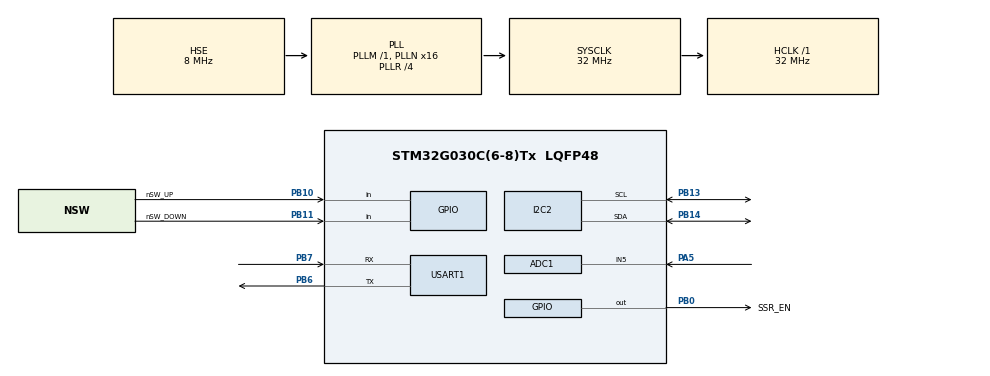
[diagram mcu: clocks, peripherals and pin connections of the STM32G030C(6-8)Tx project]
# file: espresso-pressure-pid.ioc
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ADC1.Channel-1\#ChannelRegularConversion=ADC_CHANNEL_5
ADC1.ContinuousConvMode=ENABLE
ADC1.EnableAnalogWatchDog3=true
ADC1.NbrOfConversion=1
ADC1.NbrOfConversionFlag=1
ADC1.OversamplingMode=ENABLE
ADC1.Rank-1\#ChannelRegularConversion=1
ADC1.Ratio=ADC_OVERSAMPLING_RATIO_16
ADC1.SamplingTime-1\#ChannelRegularConversion=ADC_SAMPLINGTIME_COMMON_1
ADC1.SelectedChannel=ADC_CHANNEL_5
ADC1.master=1
I2C2.Timing=0x00B07CB4
Mcu.Family=STM32G0
Mcu.Name=STM32G030C(6-8)Tx
Mcu.Package=LQFP48
PA13.Mode=Serial_Wire
PA13.Signal=SYS_SWDIO
PA14-BOOT0.Mode=Serial_Wire
PA14-BOOT0.Signal=SYS_SWCLK
PA5.Mode=IN5
PA5.Signal=ADC1_IN5
PB0.GPIO_Label=SSR_EN
PB0.Signal=GPIO_Output
PB10.GPIO_Label=nSW_UP
PB10.Signal=GPIO_Input
PB11.GPIO_Label=nSW_DOWN
PB11.Signal=GPIO_Input
PB13.Mode=I2C
PB13.Signal=I2C2_SCL
PB14.Mode=I2C
PB14.Signal=I2C2_SDA
PB6.GPIO_Speed=GPIO_SPEED_FREQ_VERY_HIGH
PB6.Mode=Asynchronous
PB6.Signal=USART1_TX
PB7.GPIO_Speed=GPIO_SPEED_FREQ_VERY_HIGH
PB7.Mode=Asynchronous
PB7.Signal=USART1_RX
PF0-OSC_IN\ (PF0).Mode=HSE-External-Oscillator
PF0-OSC_IN\ (PF0).Signal=RCC_OSC_IN
PF1-OSC_OUT\ (PF1).Mode=HSE-External-Oscillator
PF1-OSC_OUT\ (PF1).Signal=RCC_OSC_OUT
ProjectManager.HeapSize=0x200
ProjectManager.StackSize=0x400
ProjectManager.TargetToolchain=CMake
RCC.ADCFreq_Value=32000000
RCC.AHBFreq_Value=32000000
RCC.CortexFreq_Value=32000000
RCC.EXTERNAL_CLOCK_VALUE=12288000
RCC.HCLKFreq_Value=32000000
RCC.HSE_VALUE=8000000
RCC.HSI_VALUE=16000000
RCC.LSE_VALUE=32768
RCC.PLLN=16
RCC.PLLR=RCC_PLLR_DIV4
RCC.PLLSourceVirtual=RCC_PLLSOURCE_HSE
RCC.SYSCLKFreq_VALUE=32000000
RCC.SYSCLKSource=RCC_SYSCLKSOURCE_PLLCLK
RCC.USART1CLockSelection=RCC_USART1CLKSOURCE_HSI
RCC.VCOOutputFreq_Value=128000000
USART1.VirtualMode-Asynchronous=VM_ASYNC
board=custom

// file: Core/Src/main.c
/* USER CODE BEGIN Header */
/**
 ******************************************************************************
 * @file           : main.c
 * @brief          : Main program body
 ******************************************************************************
 * @attention
 *
 * Copyright (c) 2026 STMicroelectronics.
 * All rights reserved.
 *
 * This software is licensed under terms that can be found in the LICENSE file
 * in the root directory of this software component.
 * If no LICENSE file comes with this software, it is provided AS-IS.
 *
 ******************************************************************************
 */
/* USER CODE END Header */
#include "main.h"
#include "adc.h"
#include "i2c.h"
#include "usart.h"
#include "gpio.h"

/* USER CODE BEGIN Includes */
#include "app.h"
/* USER CODE END Includes */

void SystemClock_Config(void);

int main(void)
{

  /* MCU Configuration--------------------------------------------------------*/

  /* Reset of all peripherals, Initializes the Flash interface and the Systick. */
  HAL_Init();

  /* Configure the system clock */
  SystemClock_Config();

  /* Initialize all configured peripherals */
  MX_GPIO_Init();
  MX_ADC1_Init();
  MX_USART1_UART_Init();
  MX_I2C2_Init();

  /* Infinite loop */
  /* USER CODE BEGIN WHILE */
    while (1)
    {
        app();
    /* USER CODE END WHILE */

    }
}

void SystemClock_Config(void)
{
  RCC_OscInitTypeDef RCC_OscInitStruct = {0};
  RCC_ClkInitTypeDef RCC_ClkInitStruct = {0};

  /** Configure the main internal regulator output voltage
  */
  HAL_PWREx_ControlVoltageScaling(PWR_REGULATOR_VOLTAGE_SCALE1);

  /** Initializes the RCC Oscillators according to the specified parameters
  * in the RCC_OscInitTypeDef structure.
  */
  RCC_OscInitStruct.OscillatorType = RCC_OSCILLATORTYPE_HSI|RCC_OSCILLATORTYPE_HSE;
  RCC_OscInitStruct.HSEState = RCC_HSE_ON;
  RCC_OscInitStruct.HSIState = RCC_HSI_ON;
  RCC_OscInitStruct.HSIDiv = RCC_HSI_DIV1;
  RCC_OscInitStruct.HSICalibrationValue = RCC_HSICALIBRATION_DEFAULT;
  RCC_OscInitStruct.PLL.PLLState = RCC_PLL_ON;
  RCC_OscInitStruct.PLL.PLLSource = RCC_PLLSOURCE_HSE;
  RCC_OscInitStruct.PLL.PLLM = RCC_PLLM_DIV1;
  RCC_OscInitStruct.PLL.PLLN = 16;
  RCC_OscInitStruct.PLL.PLLP = RCC_PLLP_DIV2;
  RCC_OscInitStruct.PLL.PLLR = RCC_PLLR_DIV4;
  if (HAL_RCC_OscConfig(&RCC_OscInitStruct) != HAL_OK)
  {
    Error_Handler();
  }

  /** Initializes the CPU, AHB and APB buses clocks
  */
  RCC_ClkInitStruct.ClockType = RCC_CLOCKTYPE_HCLK|RCC_CLOCKTYPE_SYSCLK
                              |RCC_CLOCKTYPE_PCLK1;
  RCC_ClkInitStruct.SYSCLKSource = RCC_SYSCLKSOURCE_PLLCLK;
  RCC_ClkInitStruct.AHBCLKDivider = RCC_SYSCLK_DIV1;
  RCC_ClkInitStruct.APB1CLKDivider = RCC_HCLK_DIV1;

  if (HAL_RCC_ClockConfig(&RCC_ClkInitStruct, FLASH_LATENCY_1) != HAL_OK)
  {
    Error_Handler();
  }
}

/* USER CODE BEGIN 4 */

/* Support printf over UART */
int __io_putchar(int ch)
{
    (void)HAL_UART_Transmit(&huart1, (uint8_t*)&ch, 1, 0xFFFFU);
    return ch;
}

/* USER CODE END 4 */

void Error_Handler(void)
{
    __disable_irq();
    while (1)
    {
    }
}
